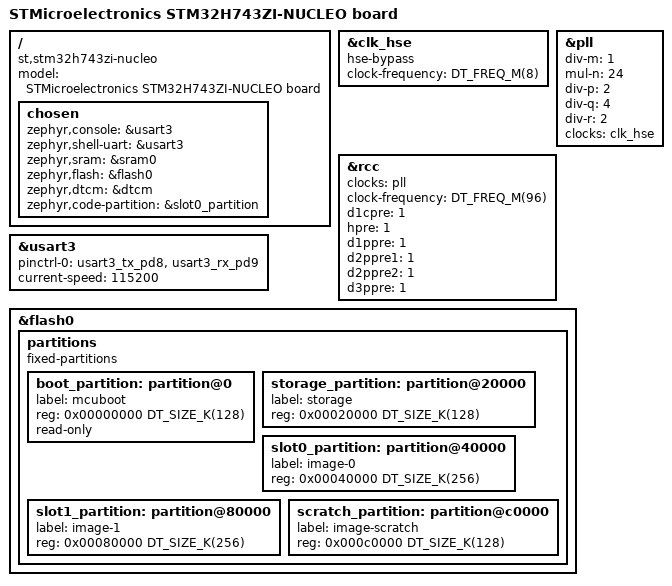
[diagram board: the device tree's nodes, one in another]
/*
 * Copyright (c) 2020 Teslabs Engineering S.L.
 *
 * SPDX-License-Identifier: Apache-2.0
 */

/dts-v1/;
#include <st/h7/stm32h743Xi.dtsi>
#include <st/h7/stm32h743zitx-pinctrl.dtsi>

/ {
	model = "STMicroelectronics STM32H743ZI-NUCLEO board";
	compatible = "st,stm32h743zi-nucleo";

	chosen {
		zephyr,console = &usart3;
		zephyr,shell-uart = &usart3;
		zephyr,sram = &sram0;
		zephyr,flash = &flash0;
		zephyr,dtcm = &dtcm;
		zephyr,code-partition = &slot0_partition;
	};
};

&clk_hse {
	hse-bypass;
	clock-frequency = <DT_FREQ_M(8)>; /* STLink 8MHz clock */
	status = "okay";
};

&pll {
	div-m = <1>;
	mul-n = <24>;
	div-p = <2>;
	div-q = <4>;
	div-r = <2>;
	clocks = <&clk_hse>;
	status = "okay";
};

&rcc {
	clocks = <&pll>;
	clock-frequency = <DT_FREQ_M(96)>;
	d1cpre = <1>;
	hpre = <1>;
	d1ppre = <1>;
	d2ppre1 = <1>;
	d2ppre2 = <1>;
	d3ppre = <1>;
};

&usart3 {
	pinctrl-0 = <&usart3_tx_pd8 &usart3_rx_pd9>;
	pinctrl-names = "default";
	current-speed = <115200>;
	status = "okay";
};

&flash0 {
	partitions {
		compatible = "fixed-partitions";
		#address-cells = <1>;
		#size-cells = <1>;

		/* 128KB for bootloader */
		boot_partition: partition@0 {
			label = "mcuboot";
			reg = <0x00000000 DT_SIZE_K(128)>;
			read-only;
		};

		/* storage: 128KB for settings */
		storage_partition: partition@20000 {
			label = "storage";
			reg = <0x00020000 DT_SIZE_K(128)>;
		};

		/* application image slot: 256KB */
		slot0_partition: partition@40000 {
			label = "image-0";
			reg = <0x00040000 DT_SIZE_K(256)>;
		};

		/* backup slot: 256KB */
		slot1_partition: partition@80000 {
			label = "image-1";
			reg = <0x00080000 DT_SIZE_K(256)>;
		};

		/* swap slot: 128KB */
		scratch_partition: partition@c0000 {
			label = "image-scratch";
			reg = <0x000c0000 DT_SIZE_K(128)>;
		};

	};
};
